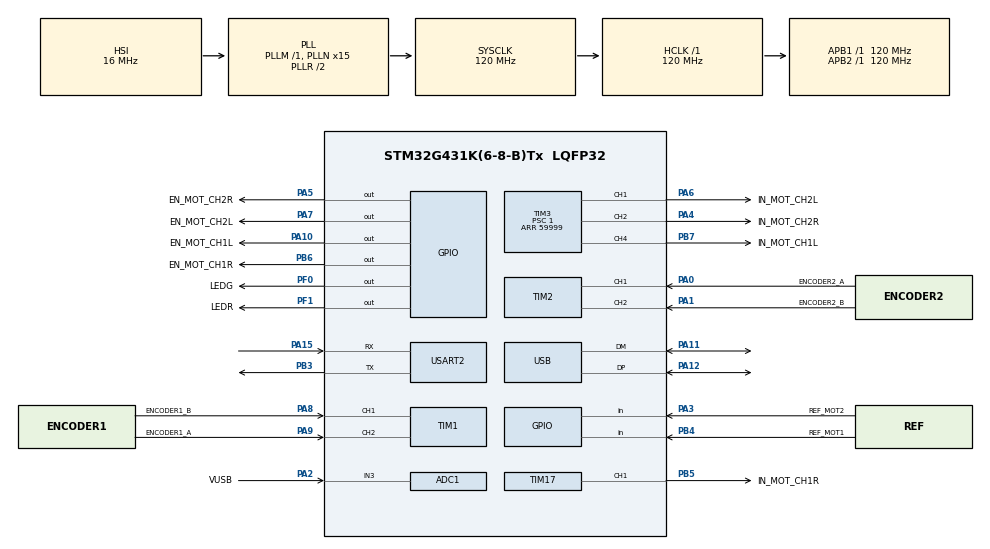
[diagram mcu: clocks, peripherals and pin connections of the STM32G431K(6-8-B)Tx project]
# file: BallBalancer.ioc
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ADC1.Channel-0\#ChannelRegularConversion=ADC_CHANNEL_3
ADC1.NbrOfConversionFlag=1
ADC1.OffsetNumber-0\#ChannelRegularConversion=ADC_OFFSET_NONE
ADC1.Rank-0\#ChannelRegularConversion=1
ADC1.SamplingTime-0\#ChannelRegularConversion=ADC_SAMPLETIME_2CYCLES_5
ADC1.master=1
Mcu.Family=STM32G4
Mcu.Name=STM32G431K(6-8-B)Tx
Mcu.Package=LQFP32
NVIC.PriorityGroup=NVIC_PRIORITYGROUP_4
NVIC.TIM4_IRQn=true\:0\:0\:false\:false\:true\:true\:true\:true
NVIC.USB_LP_IRQn=true\:0\:0\:false\:false\:true\:false\:true\:true
PA0.GPIO_Label=ENCODER2_A
PA0.Signal=S_TIM2_CH1
PA1.GPIO_Label=ENCODER2_B
PA1.Signal=S_TIM2_CH2
PA10.GPIO_Label=EN_MOT_CH1L
PA10.Signal=GPIO_Output
PA11.Mode=Device
PA11.Signal=USB_DM
PA12.Mode=Device
PA12.Signal=USB_DP
PA13.Mode=Serial_Wire
PA13.Signal=SYS_JTMS-SWDIO
PA14.Mode=Serial_Wire
PA14.Signal=SYS_JTCK-SWCLK
PA15.Mode=Asynchronous
PA15.Signal=USART2_RX
PA2.GPIO_Label=VUSB
PA2.Mode=IN3-Single-Ended
PA2.Signal=ADC1_IN3
PA3.GPIO_Label=REF_MOT2
PA3.Signal=GPIO_Input
PA4.GPIO_Label=IN_MOT_CH2R
PA4.Signal=S_TIM3_CH2
PA5.GPIO_Label=EN_MOT_CH2R
PA5.Signal=GPIO_Output
PA6.GPIO_Label=IN_MOT_CH2L
PA6.Signal=S_TIM3_CH1
PA7.GPIO_Label=EN_MOT_CH2L
PA7.Signal=GPIO_Output
PA8.GPIO_Label=ENCODER1_B
PA8.Signal=S_TIM1_CH1
PA9.GPIO_Label=ENCODER1_A
PA9.Signal=S_TIM1_CH2
PB3.Mode=Asynchronous
PB3.Signal=USART2_TX
PB4.GPIO_Label=REF_MOT1
PB4.Signal=GPIO_Input
PB5.GPIO_Label=IN_MOT_CH1R
PB5.Signal=S_TIM17_CH1
PB6.GPIO_Label=EN_MOT_CH1R
PB6.Signal=GPIO_Output
PB7.GPIO_Label=IN_MOT_CH1L
PB7.Signal=S_TIM3_CH4
PF0-OSC_IN.GPIO_Label=LEDG
PF0-OSC_IN.Signal=GPIO_Output
PF1-OSC_OUT.GPIO_Label=LEDR
PF1-OSC_OUT.Signal=GPIO_Output
ProjectManager.HeapSize=0x200
ProjectManager.StackSize=0x400
ProjectManager.TargetToolchain=STM32CubeIDE
RCC.ADC12Freq_Value=120000000
RCC.AHBFreq_Value=120000000
RCC.APB1Freq_Value=120000000
RCC.APB1TimFreq_Value=120000000
RCC.APB2Freq_Value=120000000
RCC.APB2TimFreq_Value=120000000
RCC.CK48CLockSelection=RCC_USBCLKSOURCE_HSI48
RCC.CortexFreq_Value=120000000
RCC.EXTERNAL_CLOCK_VALUE=12288000
RCC.HCLKFreq_Value=120000000
RCC.HSE_VALUE=8000000
RCC.HSI48_VALUE=48000000
RCC.HSI_VALUE=16000000
RCC.LSE_VALUE=32768
RCC.PLLN=15
RCC.SYSCLKFreq_VALUE=120000000
RCC.SYSCLKSource=RCC_SYSCLKSOURCE_PLLCLK
RCC.USBFreq_Value=48000000
RCC.VCOOutputFreq_Value=240000000
SH.S_TIM17_CH1.0=TIM17_CH1,PWM Generation1 CH1
SH.S_TIM1_CH1.0=TIM1_CH1,Encoder_Interface
SH.S_TIM1_CH2.0=TIM1_CH2,Encoder_Interface
SH.S_TIM2_CH1.0=TIM2_CH1,Encoder_Interface
SH.S_TIM2_CH2.0=TIM2_CH2,Encoder_Interface
SH.S_TIM3_CH1.0=TIM3_CH1,PWM Generation1 CH1
SH.S_TIM3_CH2.0=TIM3_CH2,PWM Generation2 CH2
SH.S_TIM3_CH4.0=TIM3_CH4,PWM Generation4 CH4
TIM17.Channel=TIM_CHANNEL_1
TIM17.PeriodNoDither=59999
TIM17.Prescaler=1
TIM3.Channel-PWM\ Generation1\ CH1=TIM_CHANNEL_1
TIM3.Channel-PWM\ Generation2\ CH2=TIM_CHANNEL_2
TIM3.Channel-PWM\ Generation4\ CH4=TIM_CHANNEL_4
TIM3.PeriodNoDither=59999
TIM3.Prescaler=1
TIM4.PeriodNoDither=59999
TIM4.Prescaler=1
USART2.VirtualMode-Asynchronous=VM_ASYNC
USB_DEVICE.CLASS_NAME_FS=CDC
USB_DEVICE.VirtualMode=Cdc
USB_DEVICE.VirtualModeFS=Cdc_FS
VP_SYS_VS_DBSignals.Mode=DisableDeadBatterySignals
VP_TIM17_VS_ClockSourceINT.Mode=Enable_Timer
VP_TIM4_VS_ClockSourceINT.Mode=Internal
VP_USB_DEVICE_VS_USB_DEVICE_CDC_FS.Mode=CDC_FS
board=custom

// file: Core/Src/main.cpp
/* USER CODE BEGIN Header */
/**
  ******************************************************************************
  * @file           : main.c
  * @brief          : Main program body
  ******************************************************************************
  * @attention
  *
  * Copyright (c) 2024 STMicroelectronics.
  * All rights reserved.
  *
  * This software is licensed under terms that can be found in the LICENSE file
  * in the root directory of this software component.
  * If no LICENSE file comes with this software, it is provided AS-IS.
  *
  ******************************************************************************
  */
/* USER CODE END Header */
#include "main.h"
#include "adc.h"
#include "tim.h"
#include "usart.h"
#include "usb_device.h"
#include "gpio.h"

/* USER CODE BEGIN Includes */
#include "AppMain/ApplicationMain.h"
/* USER CODE END Includes */

/* USER CODE BEGIN PTD */
  ApplicationMain applicationMain = ApplicationMain();
/* USER CODE END PTD */

void SystemClock_Config(void);

int main(void)
{

  /* MCU Configuration--------------------------------------------------------*/

  /* Reset of all peripherals, Initializes the Flash interface and the Systick. */
  HAL_Init();

  /* Configure the system clock */
  SystemClock_Config();

  /* Initialize all configured peripherals */
  MX_GPIO_Init();
  MX_ADC1_Init();
  MX_TIM1_Init();
  MX_TIM2_Init();
  MX_TIM3_Init();
  MX_TIM4_Init();
  MX_TIM17_Init();
  MX_USART2_UART_Init();
  MX_USB_Device_Init();
  /* USER CODE BEGIN 2 */
  applicationMain.StartUp();
  /* USER CODE END 2 */

  /* Infinite loop */
  while (1)
  {

  }
}

void SystemClock_Config(void)
{
  RCC_OscInitTypeDef RCC_OscInitStruct = {0};
  RCC_ClkInitTypeDef RCC_ClkInitStruct = {0};

  /** Configure the main internal regulator output voltage
  */
  HAL_PWREx_ControlVoltageScaling(PWR_REGULATOR_VOLTAGE_SCALE1);

  /** Initializes the RCC Oscillators according to the specified parameters
  * in the RCC_OscInitTypeDef structure.
  */
  RCC_OscInitStruct.OscillatorType = RCC_OSCILLATORTYPE_HSI|RCC_OSCILLATORTYPE_HSI48;
  RCC_OscInitStruct.HSIState = RCC_HSI_ON;
  RCC_OscInitStruct.HSICalibrationValue = RCC_HSICALIBRATION_DEFAULT;
  RCC_OscInitStruct.HSI48State = RCC_HSI48_ON;
  RCC_OscInitStruct.PLL.PLLState = RCC_PLL_ON;
  RCC_OscInitStruct.PLL.PLLSource = RCC_PLLSOURCE_HSI;
  RCC_OscInitStruct.PLL.PLLM = RCC_PLLM_DIV1;
  RCC_OscInitStruct.PLL.PLLN = 15;
  RCC_OscInitStruct.PLL.PLLP = RCC_PLLP_DIV2;
  RCC_OscInitStruct.PLL.PLLQ = RCC_PLLQ_DIV2;
  RCC_OscInitStruct.PLL.PLLR = RCC_PLLR_DIV2;
  if (HAL_RCC_OscConfig(&RCC_OscInitStruct) != HAL_OK)
  {
    Error_Handler();
  }

  /** Initializes the CPU, AHB and APB buses clocks
  */
  RCC_ClkInitStruct.ClockType = RCC_CLOCKTYPE_HCLK|RCC_CLOCKTYPE_SYSCLK
                              |RCC_CLOCKTYPE_PCLK1|RCC_CLOCKTYPE_PCLK2;
  RCC_ClkInitStruct.SYSCLKSource = RCC_SYSCLKSOURCE_PLLCLK;
  RCC_ClkInitStruct.AHBCLKDivider = RCC_SYSCLK_DIV1;
  RCC_ClkInitStruct.APB1CLKDivider = RCC_HCLK_DIV1;
  RCC_ClkInitStruct.APB2CLKDivider = RCC_HCLK_DIV1;

  if (HAL_RCC_ClockConfig(&RCC_ClkInitStruct, FLASH_LATENCY_3) != HAL_OK)
  {
    Error_Handler();
  }
}

/* USER CODE BEGIN 4 */
void HAL_TIM_PeriodElapsedCallback(TIM_HandleTypeDef *htim){

	if(htim->Instance == TIM4){
		applicationMain.taskhandler.UpdateTaskhandler();
	}

}
/* USER CODE END 4 */

void Error_Handler(void)
{
  __disable_irq();
  while (1)
  {
  }
}
